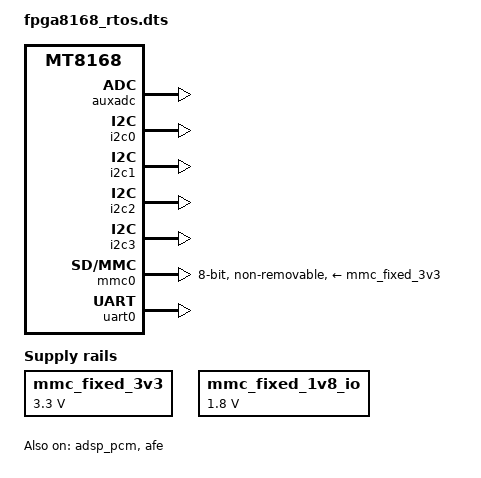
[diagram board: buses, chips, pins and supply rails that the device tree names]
/*
 * Copyright (c) 2019 MediaTek Inc.
 *
 * This program is free software; you can redistribute it and/or modify
 * it under the terms of the GNU General Public License version 2 as
 * published by the Free Software Foundation.
 *
 * This program is distributed in the hope that it will be useful,
 * MERCHANTABILITY or FITNESS FOR A PARTICULAR PURPOSE.  See the
 * GNU General Public License for more details.
 */

/dts-v1/;
#include "mt8168.dtsi"

/ {
	mmc_fixed_3v3: fixedregulator@0 {
		compatible = "regulator-fixed";
		regulator-name = "mmc_power";
		regulator-min-microvolt = <3300000>;
		regulator-max-microvolt = <3300000>;
		enable-active-high;
		regulator-always-on;
	};

	mmc_fixed_1v8_io: fixedregulator@1 {
		compatible = "regulator-fixed";
		regulator-name = "mmc_io";
		regulator-min-microvolt = <1800000>;
		regulator-max-microvolt = <1800000>;
		enable-active-high;
		regulator-always-on;
	};

	sound: sound {
		compatible = "mediatek,mt8168-ep";
		mediatek,platform = <&afe>;
		mediatek,adsp-platform = <&adsp_pcm>;
		status = "okay";
	};
};

&adsp_pcm {
	status = "okay";
};

&afe {
	status = "okay";
};

&atf_reserved_memory {
	reg = <0 0x43000000 0 0x30000>;
};

&auxadc {
	status = "okay";
};

&chosen {
	bootargs = "console=tty0 console=ttyS0,921600n1 \
		    earlycon=uart8250,mmio32,0x11002000 vmalloc=496M \
		    clk_ignore_unused pd_ignore_unused \
		    skip_initramfs rootwait ro init=/sbin/init \
		    root=/dev/mmcblk0p7 boot_reason=0";
};

&cpu0 {
	clock-frequency = <10000000>;
};

&cpu1 {
	clock-frequency = <10000000>;
};

&cpu2 {
	clock-frequency = <10000000>;
};

&cpu3 {
	clock-frequency = <10000000>;
};

&ethernet {
	status = "disabled";
};

&i2c0 {
	status = "okay";
};

&i2c1 {
	status = "okay";
};

&i2c2 {
	status = "okay";
};

&i2c3 {
	status = "okay";
};

&mmc0 {
	status = "okay";
	bus-width = <8>;
	max-frequency = <5000000>;
	cap-mmc-highspeed;
	vmmc-supply = <&mmc_fixed_3v3>;
	vqmmc-supply = <&mmc_fixed_1v8_io>;
	non-removable;
	no-sd;
	no-sdio;
};

&reserved_memory {
	#address-cells = <2>;
	#size-cells = <2>;

	consys-reserve-memory {
		compatible = "mediatek,consys-reserve-memory";
		no-map;
		size = <0 0x200000>;
		alignment = <0 0x200000>;
	};

	mtee-reserved-memory {
		compatible = "mediatek,mt8168-mtee-reserved-memory";
		no-map;
		reg = <0 0x5fc00000 0 0x400000>;
	};
};

&timer {
	clock-frequency = <10000000>;
};

&uart_clk {
	clock-frequency = <10000000>;
};

&uart0 {
	status="okay";
};

